# ATSAMRH707F18A register map
Vendor: Microchip Technology; Series: SAMRH707; File version: 0
CPU: CM7 r1p1, little endian, MPU, FPU, 3 interrupt priority bits
Registers are 32-bit, read-write, reset 0x0 unless marked. A register's access mark holds for its fields unless they carry their own. Offsets are from the block's base; [hi:lo] are bit positions; {n}, {i} and the like mark numbered series; 'fields as' and 'values as' point back to an identical list.

## RSWDT — Reinforced Safety Watchdog Timer
Base 0x40100300; register names take the prefix RSWDT_
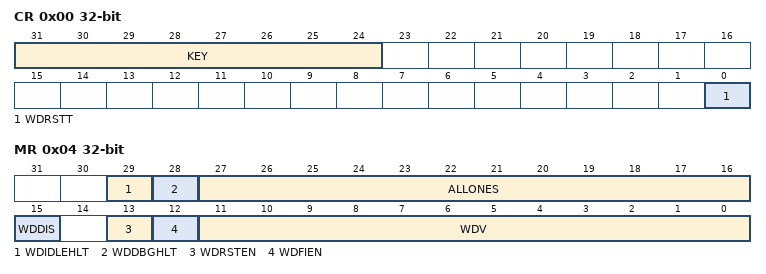
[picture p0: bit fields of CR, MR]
0x00 CR wo — Control Register
  [31:24] KEY — Password
    196=PASSWD (Writing any other value in this field aborts the write operation.)
  [0] WDRSTT — Watchdog Restart
0x04 MR — Mode Register
  [29] WDIDLEHLT — Watchdog Idle Halt
  [28] WDDBGHLT — Watchdog Debug Halt
  [27:16] ALLONES — Must Always Be Written with 0xFFF
  [15] WDDIS — Watchdog Disable
  [13] WDRSTEN — Watchdog Reset Enable
  [12] WDFIEN — Watchdog Fault Interrupt Enable
  [11:0] WDV — Watchdog Counter Value
0x08 SR ro — Status Register
  [0] WDUNF — Watchdog Underflow

## RTT — Real-time Timer
Base 0x40100230; register names take the prefix RTT_
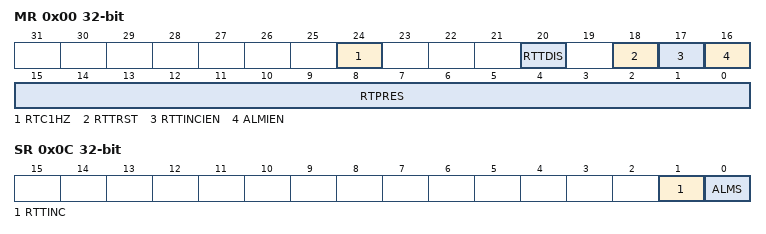
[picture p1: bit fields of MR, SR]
0x00 MR — Mode Register
  [24] RTC1HZ — Real-Time Clock 1Hz Clock Selection
  [20] RTTDIS — Real-time Timer Disable
  [18] RTTRST — Real-time Timer Restart
  [17] RTTINCIEN — Real-time Timer Increment Interrupt Enable
  [16] ALMIEN — Alarm Interrupt Enable
  [15:0] RTPRES — Real-time Timer Prescaler Value
0x04 AR — Alarm Register
  [31:0] ALMV — Alarm Value
0x08 VR ro — Value Register
  [31:0] CRTV — Current Real-time Value
0x0C SR ro — Status Register
  [1] RTTINC — Prescaler Roll-over Status (cleared on read)
  [0] ALMS — Real-time Alarm Status (cleared on read)

## SFR — Special Function Registers
Base 0x400A0000; register names take the prefix SFR_
{0x0+4i} ROMCODE_DBG[{i}] (i=0..39) — ROM code debug
  [31:0] ROM_CODE_DEBUG — Rom code debug step
0xA0 CAN0 — CAN0 MSB Base Address
  [31:16] EXT_MEM_ADDR — MSB Base Address
0xA4 CAN1 — CAN1 MSB Base Address
  [31:16] EXT_MEM_ADDR — MSB Base Address
0xB0 BOOT_CFG — BOOT Configuration
  [2:0] BOOT_SEL — BOOT_MODE selected
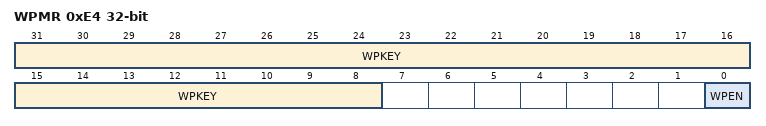
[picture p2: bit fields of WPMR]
0xE4 WPMR — Write Protection Mode Register
  [31:8] WPKEY — Write Protection Key
    0x534652=PASSWD (Writing any other value in this field aborts the write operation of the WPEN bit. Always reads as 0.)
  [0] WPEN — Write Protection Enable

## SUPC — Supply Controller
Base 0x40100210; register names take the prefix SUPC_
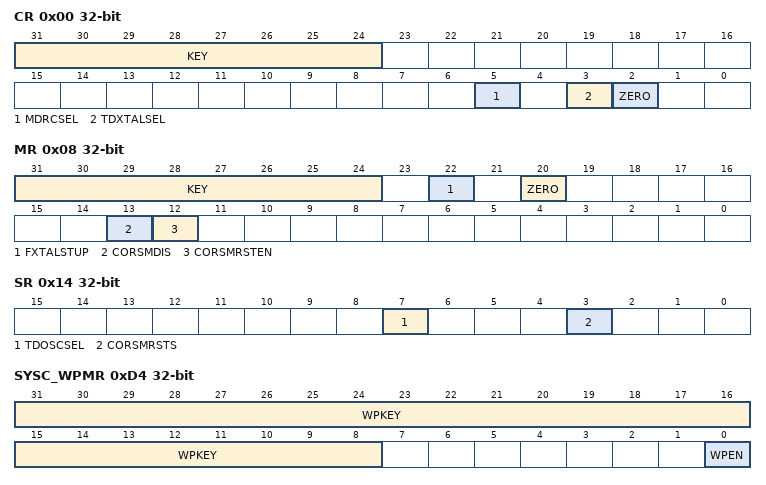
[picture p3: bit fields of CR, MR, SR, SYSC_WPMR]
0x00 CR wo — Supply Controller Control Register
  [31:24] KEY — Password
    165=PASSWD (Writing any other value in this field aborts the write operation.)
  [5] MDRCSEL — Monitoring Domain RC Oscillator Select
    0=NO_EFFECT; 1=CRYSTAL_SEL (If KEY is correct, XTALSEL switches the slow clock of the monitoring domain (MD_SLCK) on the slow RC oscillator output.)
  [3] TDXTALSEL — Timing Domain Crystal Oscillator Select
    0=NO_EFFECT; 1=CRYSTAL_SEL (If KEY is correct, XTALSEL switches the slow clock of the timing domain (TD_SLCK) on the 32.768 kHz crystal oscillator output.)
  [2] ZERO — Shall be always write at '0'
0x04 SMMR — Supply Controller Supply Monitor Mode Register
  [23] CORESMUSEL — Core Supply Monitor User Selection
0x08 MR — Supply Controller Mode Register
  [31:24] KEY — Password Key
    values as CR.KEY
  [22] FXTALSTUP — Fast Startup 32.768 kHz Crystal Oscillator
  [20] ZERO — Shall be always write at '0'
  [13] CORSMDIS — VDDCORE Supply Monitor Disable
    0=ENABLE (The VDDCORE supply monitor is enabled.); 1=DISABLE (The VDDCORE supply monitor is disabled.)
  [12] CORSMRSTEN — VDDCORE Supply Monitor Reset Enable
    0=NOT_ENABLE (The core reset signal vddcore_nreset is not affected when a VDDCORE supply monitor detection occurs.); 1=ENABLE (The core reset signal, vddcore_nreset is asserted when a VDDCORE supply monitor detection occurs.)
0x14 SR ro — Supply Controller Status Register
  [7] TDOSCSEL — 32 kHz Oscillator Selection Status
    0=RC (The timing domain slow clock, TD_SLCK, is generated by the slow RC oscillator.); 1=CRYST (The timing domain slow clock, TD_SLCK, is generated by the 32.768 kHz crystal oscillator.)
  [3] CORSMRSTS — VDDCORE Supply Monitor Reset Status (cleared on read)
    0=NO (No VDDCORE Supply Monitor reset event has been detected since the last read of the SUPC_SR.); 1=PRESENT (At least one VDDCORE Supply Monitor reset event has been detected since the last read of the SUPC_SR.)
0x1C PWR — Supply Controller Power Register
  [18] ZERO — MD_SLCK always generated by the slow RC oscillator
0xD4 SYSC_WPMR — Write Protection Mode Register
  [31:8] WPKEY — Write Protection Key.
    0x525443=PASSWD (Writing any other value in this field aborts the write operation of the WPEN bit. Always reads as 0.)
  [0] WPEN — Write Protection Enable
